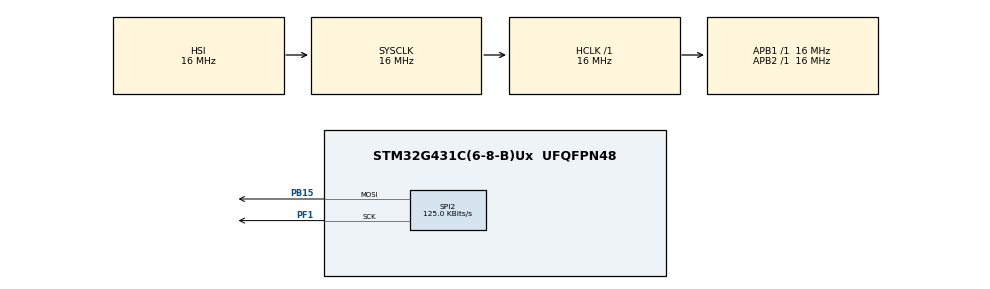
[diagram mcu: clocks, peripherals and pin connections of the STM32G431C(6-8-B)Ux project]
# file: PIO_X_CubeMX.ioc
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Mcu.Family=STM32G4
Mcu.Name=STM32G431C(6-8-B)Ux
Mcu.Package=UFQFPN48
NVIC.PriorityGroup=NVIC_PRIORITYGROUP_4
PB15.Mode=TX_Only_Simplex_Unidirect_Master
PB15.Signal=SPI2_MOSI
PF1-OSC_OUT.Mode=TX_Only_Simplex_Unidirect_Master
PF1-OSC_OUT.Signal=SPI2_SCK
ProjectManager.HeapSize=0x200
ProjectManager.StackSize=0x400
ProjectManager.TargetToolchain=Makefile
RCC.AHBFreq_Value=16000000
RCC.APB1Freq_Value=16000000
RCC.APB1TimFreq_Value=16000000
RCC.APB2Freq_Value=16000000
RCC.APB2TimFreq_Value=16000000
RCC.CortexFreq_Value=16000000
RCC.EXTERNAL_CLOCK_VALUE=12288000
RCC.HCLKFreq_Value=16000000
RCC.HSE_VALUE=8000000
RCC.HSI48_VALUE=48000000
RCC.HSI_VALUE=16000000
RCC.LSE_VALUE=32768
RCC.SYSCLKFreq_VALUE=16000000
RCC.USBFreq_Value=64000000
RCC.VCOOutputFreq_Value=128000000
SPI2.BaudRatePrescaler=SPI_BAUDRATEPRESCALER_128
SPI2.CalculateBaudRate=125.0 KBits/s
SPI2.DataSize=SPI_DATASIZE_8BIT
SPI2.Direction=SPI_DIRECTION_2LINES
SPI2.Mode=SPI_MODE_MASTER
SPI2.VirtualType=VM_MASTER
VP_SYS_VS_DBSignals.Mode=DisableDeadBatterySignals
board=custom

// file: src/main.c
/* USER CODE BEGIN Header */
/**
 ******************************************************************************
 * @file           : main.c
 * @brief          : Main program body
 ******************************************************************************
 * @attention
 *
 * Copyright (c) 2025 STMicroelectronics.
 * All rights reserved.
 *
 * This software is licensed under terms that can be found in the LICENSE file
 * in the root directory of this software component.
 * If no LICENSE file comes with this software, it is provided AS-IS.
 *
 ******************************************************************************
 */
/* USER CODE END Header */
#include "main.h"

SPI_HandleTypeDef hspi2;

void SystemClock_Config(void);
static void MX_GPIO_Init(void);
static void MX_SPI2_Init(void);

/* USER CODE BEGIN 0 */
#include <ssd1306.h>

/* USER CODE END 0 */

int main(void)
{

  /* MCU Configuration--------------------------------------------------------*/

  /* Reset of all peripherals, Initializes the Flash interface and the Systick. */
  HAL_Init();

  /* USER CODE BEGIN Init */
  ssd1306_Init();
  ssd1306_Fill(White);
  ssd1306_UpdateScreen();
  /* USER CODE END Init */

  /* Configure the system clock */
  SystemClock_Config();

  /* Initialize all configured peripherals */
  MX_GPIO_Init();
  MX_SPI2_Init();

  /* Infinite loop */
  /* USER CODE BEGIN WHILE */
  while (1) {
    ssd1306_Fill(Black);
    ssd1306_DrawCircle(25, 25, 25, White);
    ssd1306_UpdateScreen();
    /* USER CODE END WHILE */

  }
}

void SystemClock_Config(void)
{
  RCC_OscInitTypeDef RCC_OscInitStruct = {0};
  RCC_ClkInitTypeDef RCC_ClkInitStruct = {0};

  /** Configure the main internal regulator output voltage
  */
  HAL_PWREx_ControlVoltageScaling(PWR_REGULATOR_VOLTAGE_SCALE1);

  /** Initializes the RCC Oscillators according to the specified parameters
  * in the RCC_OscInitTypeDef structure.
  */
  RCC_OscInitStruct.OscillatorType = RCC_OSCILLATORTYPE_HSI;
  RCC_OscInitStruct.HSIState = RCC_HSI_ON;
  RCC_OscInitStruct.HSICalibrationValue = RCC_HSICALIBRATION_DEFAULT;
  RCC_OscInitStruct.PLL.PLLState = RCC_PLL_NONE;
  if (HAL_RCC_OscConfig(&RCC_OscInitStruct) != HAL_OK)
  {
    Error_Handler();
  }

  /** Initializes the CPU, AHB and APB buses clocks
  */
  RCC_ClkInitStruct.ClockType = RCC_CLOCKTYPE_HCLK|RCC_CLOCKTYPE_SYSCLK
                              |RCC_CLOCKTYPE_PCLK1|RCC_CLOCKTYPE_PCLK2;
  RCC_ClkInitStruct.SYSCLKSource = RCC_SYSCLKSOURCE_HSI;
  RCC_ClkInitStruct.AHBCLKDivider = RCC_SYSCLK_DIV1;
  RCC_ClkInitStruct.APB1CLKDivider = RCC_HCLK_DIV1;
  RCC_ClkInitStruct.APB2CLKDivider = RCC_HCLK_DIV1;

  if (HAL_RCC_ClockConfig(&RCC_ClkInitStruct, FLASH_LATENCY_0) != HAL_OK)
  {
    Error_Handler();
  }
}

static void MX_SPI2_Init(void)
{

  /* SPI2 parameter configuration*/
  hspi2.Instance = SPI2;
  hspi2.Init.Mode = SPI_MODE_MASTER;
  hspi2.Init.Direction = SPI_DIRECTION_2LINES;
  hspi2.Init.DataSize = SPI_DATASIZE_8BIT;
  hspi2.Init.CLKPolarity = SPI_POLARITY_LOW;
  hspi2.Init.CLKPhase = SPI_PHASE_1EDGE;
  hspi2.Init.NSS = SPI_NSS_SOFT;
  hspi2.Init.BaudRatePrescaler = SPI_BAUDRATEPRESCALER_128;
  hspi2.Init.FirstBit = SPI_FIRSTBIT_MSB;
  hspi2.Init.TIMode = SPI_TIMODE_DISABLE;
  hspi2.Init.CRCCalculation = SPI_CRCCALCULATION_DISABLE;
  hspi2.Init.CRCPolynomial = 7;
  hspi2.Init.CRCLength = SPI_CRC_LENGTH_DATASIZE;
  hspi2.Init.NSSPMode = SPI_NSS_PULSE_ENABLE;
  if (HAL_SPI_Init(&hspi2) != HAL_OK)
  {
    Error_Handler();
  }

}

static void MX_GPIO_Init(void)
{

  /* GPIO Ports Clock Enable */
  __HAL_RCC_GPIOF_CLK_ENABLE();
  __HAL_RCC_GPIOB_CLK_ENABLE();

}

void Error_Handler(void)
{
  __disable_irq();
  while (1) {
  }
}
#ifdef USE_FULL_ASSERT
/**
  * @brief  Reports the name of the source file and the source line number
  *         where the assert_param error has occurred.
  * @param  file: pointer to the source file name
  * @param  line: assert_param error line source number
  * @retval None
  */
void assert_failed(uint8_t *file, uint32_t line)
{
  /* USER CODE BEGIN 6 */
  /* User can add his own implementation to report the file name and line
     number, ex: printf("Wrong parameters value: file %s on line %d\r\n", file,
     line) */
  /* USER CODE END 6 */
}
#endif /* USE_FULL_ASSERT */
